# S6E1A1 register map
File version: 1.1
Registers are 8-bit, read-write, reset 0x0 unless marked. A register's access mark holds for its fields unless they carry their own. Offsets are from the block's base; [hi:lo] are bit positions; 'fields as' and 'values as' point back to an identical list.

## MFT0 — Multifunction Timer 0
Base 0x40020000
0x102 OCU_OCCP0 16-bit — OCU ch.0 Compare Value Store Register
0x106 OCU_OCCP1 16-bit — OCU ch.1 Compare Value Store Register
0x10A OCU_OCCP2 16-bit — OCU ch.2 Compare Value Store Register
0x10E OCU_OCCP3 16-bit — OCU ch.3 Compare Value Store Register
0x112 OCU_OCCP4 16-bit — OCU ch.4 Compare Value Store Register
0x116 OCU_OCCP5 16-bit — OCU ch.5 Compare Value Store Register
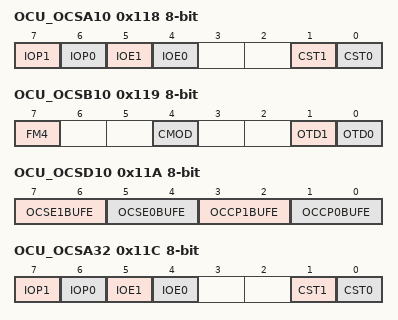
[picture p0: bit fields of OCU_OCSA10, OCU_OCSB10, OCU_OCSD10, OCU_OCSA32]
0x118 OCU_OCSA10 — OCU ch.1@0 Control Register A
  [7] IOP1 — Indicates that a match has already been detected between FRT's count value and OCCP(1) value at OCU ch.(1).
  [6] IOP0 — Indicates that a match has already been detected between FRT's count value and OCCP(0) value at OCU ch.(0).
  [5] IOE1 — Generates interrupt@ when ""1"" is set to OCSA.IOP1
  [4] IOE0 — Generates interrupt@ when ""1"" is set to OCSA.IOP0
  [1] CST1 — Enables the operation of OCU ch.(1)
  [0] CST0 — Enables the operation of OCU ch.(0)
0x119 OCU_OCSB10 — OCU ch.1@0 Control Register B
  [7] FM4 — Selects the OCU's operating mode
  [4] CMOD — Selects OCU's operation mode in combination with OCSC.MOD0 to MOD5
  [1] OTD1 — Indicates that the RT(1) output pin is in the High-level output state.
  [0] OTD0 — Indicates that the RT(0) output pin is in the High-level output state.
0x11A OCU_OCSD10 — OCU ch.1@0 Control Register D
  [7:6] OCSE1BUFE — Enable or disable the buffer register function of OCSE(1)
  [5:4] OCSE0BUFE — Enable or disable the buffer register function of OCSE(0)
  [3:2] OCCP1BUFE — Enable or disable the buffer register function of OCCP(1)
  [1:0] OCCP0BUFE — Enable or disable the buffer register function of OCCP(0)
0x11C OCU_OCSA32 — OCU ch.3@2 Control Register A
  fields as OCU_OCSA10
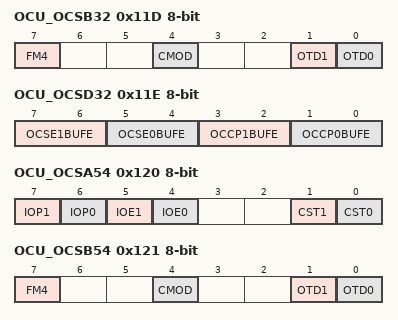
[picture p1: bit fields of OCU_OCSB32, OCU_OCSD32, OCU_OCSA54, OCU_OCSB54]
0x11D OCU_OCSB32 — OCU ch.3@2 Control Register B
  fields as OCU_OCSB10
0x11E OCU_OCSD32 — OCU ch.1@0 Control Register D
  fields as OCU_OCSD10
0x120 OCU_OCSA54 — OCU ch.5@4 Control Register A
  fields as OCU_OCSA10
0x121 OCU_OCSB54 — OCU ch.5@4 Control Register B
  fields as OCU_OCSB10
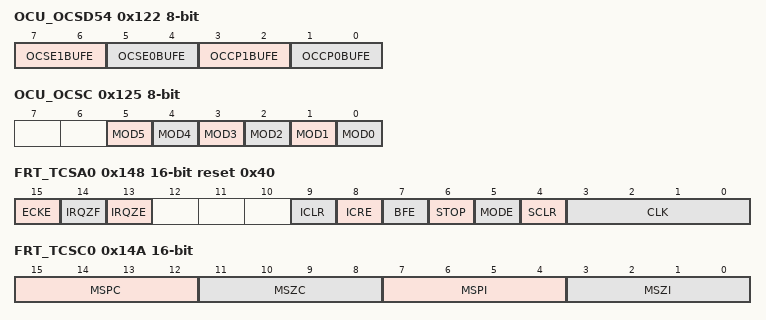
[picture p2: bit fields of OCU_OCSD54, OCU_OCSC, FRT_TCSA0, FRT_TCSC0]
0x122 OCU_OCSD54 — OCU ch.5@4 Control Register D
  fields as OCU_OCSD10
0x125 OCU_OCSC — OCU Control Register C
  [5] MOD5 — OCSC.MOD4 and OCSC.MOD5 determine the operation mode of OCU ch.4,h.5 in combination with OCSB54.CMOD
  [4] MOD4 — OCSC.MOD4 and OCSC.MOD5 determine the operation mode of OCU ch.4,h.5 in combination with OCSB54.CMOD
  [3] MOD3 — OCSC.MOD2 and OCSC.MOD3 determine the operation mode of OCU ch.2,h.3 in combination with OCSB32.CMOD
  [2] MOD2 — OCSC.MOD2 and OCSC.MOD3 determine the operation mode of OCU ch.2,h.3 in combination with OCSB32.CMOD
  [1] MOD1 — OCSC.MOD0 and OCSC.MOD1 determine the operation mode of OCU ch.0,h.1 in combination with OCSB10.CMOD
  [0] MOD0 — OCSC.MOD0 and OCSC.MOD1 determine the operation mode of OCU ch.0,h.1 in combination with OCSB10.CMOD
0x128 OCU_OCSE0 16-bit — OCU ch.0 Control Register E
  [15:0] OCSE — Specify the setting conditions of the OCU's matching detection register and the change conditions for output signals
0x12C OCU_OCSE1 32-bit — OCU ch.1 Control Register E
  [31:0] OCSE — Specify the setting conditions of the OCU's matching detection register and the change conditions for output signals
0x130 OCU_OCSE2 16-bit — OCU ch.2 Control Register E
  fields as OCU_OCSE0
0x134 OCU_OCSE3 32-bit — OCU ch.3 Control Register E
  fields as OCU_OCSE1
0x138 OCU_OCSE4 16-bit — OCU ch.4 Control Register E
  fields as OCU_OCSE0
0x13C OCU_OCSE5 32-bit — OCU ch.5 Control Register E
  fields as OCU_OCSE1
0x142 FRT_TCCP0 16-bit reset 0xFFFF — FRT-ch.0 Cycle Setting Register
0x146 FRT_TCDT0 16-bit — FRT-ch.0 Count Value Register
0x148 FRT_TCSA0 16-bit reset 0x40 — FRT-ch.0 Control Register A
  [15] ECKE — Uses an external input clock (FRCK) as FRT's count clock
  [14] IRQZF — Zero interrupt flag
  [13] IRQZE — Generates interrupt@ when ""1"" is set to TCSA.IRQZF
  [9] ICLR — Interrupt flag
  [8] ICRE — Generates interrupt when ""1"" is set to TCSA.ICLR
  [7] BFE — Enables TCCP's buffer function
  [6] STOP — Puts FRT in stopping state
  [5] MODE — FRT's count mode
  [4] SCLR wo — FRT operation state initialization request
  [3:0] CLK — FRT clock cycle
0x14A FRT_TCSC0 16-bit — FRT-ch.0 Control Register C
  [15:12] MSPC ro — Sets the number of masked Zero value detections
  [11:8] MSZC ro — Sets the number of masked Peak value detections
  [7:4] MSPI — Reads the current counter value from a Zero value detection mask counter
  [3:0] MSZI — Reads the current counter value from a Peak value detection mask counter
0x14E FRT_TCCP1 16-bit reset 0xFFFF — FRT-ch.1 Cycle Setting Register
0x152 FRT_TCDT1 16-bit — FRT-ch.1 Count Value Register
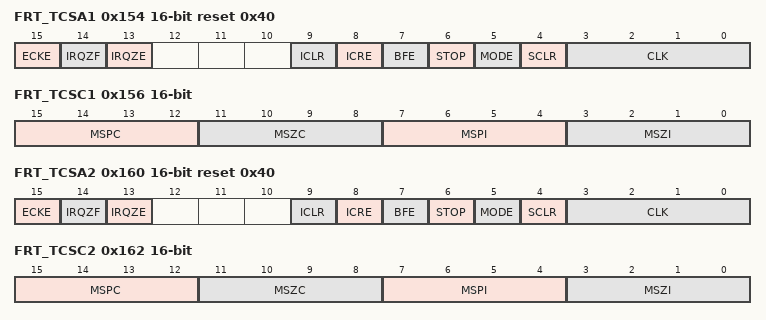
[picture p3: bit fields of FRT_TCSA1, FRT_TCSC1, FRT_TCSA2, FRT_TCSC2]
0x154 FRT_TCSA1 16-bit reset 0x40 — FRT-ch.1 Control Register A
  fields as FRT_TCSA0
0x156 FRT_TCSC1 16-bit — FRT-ch.1 Control Register C
  fields as FRT_TCSC0
0x15A FRT_TCCP2 16-bit reset 0xFFFF — FRT-ch.2 Cycle Setting Register
0x15E FRT_TCDT2 16-bit — FRT-ch.2 Count Value Register
0x160 FRT_TCSA2 16-bit reset 0x40 — FRT-ch.2 Control Register A
  fields as FRT_TCSA0
0x162 FRT_TCSC2 16-bit — FRT-ch.2 Control Register C
  fields as FRT_TCSC0
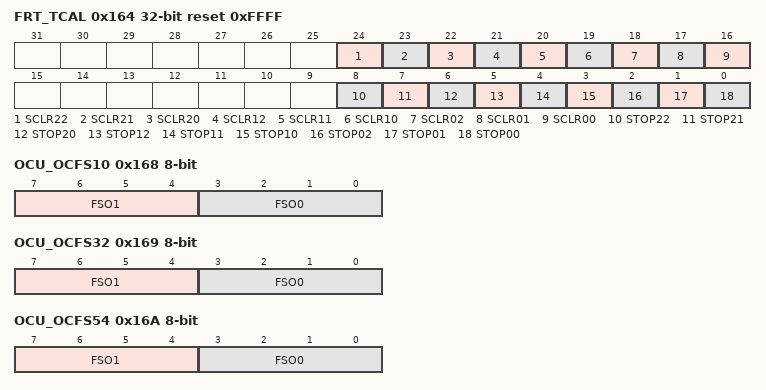
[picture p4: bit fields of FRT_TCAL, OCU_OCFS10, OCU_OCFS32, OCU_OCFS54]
0x164 FRT_TCAL 32-bit reset 0xFFFF — FRT Simultaneous Start Control Register
  [24] SCLR22 wo — Processes simultaneous writes to relevant TCSA.SCLR register 22
  [23] SCLR21 wo — Processes simultaneous writes to relevant TCSA.SCLR register 21
  [22] SCLR20 wo — Processes simultaneous writes to relevant TCSA.SCLR register 20
  [21] SCLR12 wo — Processes simultaneous writes to relevant TCSA.SCLR register 12
  [20] SCLR11 wo — Processes simultaneous writes to relevant TCSA.SCLR register 11
  [19] SCLR10 wo — Processes simultaneous writes to relevant TCSA.SCLR register 10
  [18] SCLR02 wo — Processes simultaneous writes to relevant TCSA.SCLR register 02
  [17] SCLR01 wo — Processes simultaneous writes to relevant TCSA.SCLR register 01
  [16] SCLR00 wo — Processes simultaneous writes to relevant TCSA.SCLR register 00
  [8] STOP22 — Processes simultaneous writes/reads to relevant TCSA.STOP bit 22
  [7] STOP21 — Processes simultaneous writes/reads to relevant TCSA.STOP bit 21
  [6] STOP20 — Processes simultaneous writes/reads to relevant TCSA.STOP bit 20
  [5] STOP12 — Processes simultaneous writes/reads to relevant TCSA.STOP bit 12
  [4] STOP11 — Processes simultaneous writes/reads to relevant TCSA.STOP bit 11
  [3] STOP10 — Processes simultaneous writes/reads to relevant TCSA.STOP bit 10
  [2] STOP02 — Processes simultaneous writes/reads to relevant TCSA.STOP bit 02
  [1] STOP01 — Processes simultaneous writes/reads to relevant TCSA.STOP bit 01
  [0] STOP00 — Processes simultaneous writes/reads to relevant TCSA.STOP bit 00
0x168 OCU_OCFS10 — OCU ch.1@0 Connecting FRT Select Register
  [7:4] FSO1 — Connects FRT ch.x to OCU ch.1
  [3:0] FSO0 — Connects FRT ch.x to OCU ch.0
0x169 OCU_OCFS32 — OCU ch.3@2 Connecting FRT Select Register
  fields as OCU_OCFS10
0x16A OCU_OCFS54 — OCU ch.5@4 Connecting FRT Select Register
  fields as OCU_OCFS10
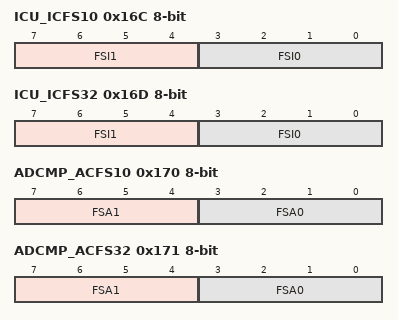
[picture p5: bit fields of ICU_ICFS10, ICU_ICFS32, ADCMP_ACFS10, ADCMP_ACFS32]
0x16C ICU_ICFS10 — ICU ch.1@0 Connecting FRT Select Register
  [7:4] FSI1 — Connects FRT ch.x to ICU ch.(1)
  [3:0] FSI0 — Connects FRT ch.x to ICU ch.(0)
0x16D ICU_ICFS32 — ICU ch.3@2 Connecting FRT Select Register
  fields as ICU_ICFS10
0x170 ADCMP_ACFS10 — ADCMP Ch1@0 Connecting FRT Select Register
  [7:4] FSA1 — Specify the FRT ch.x to be connected to ADCMP ch.(1)
  [3:0] FSA0 — Specify the FRT ch.x to be connected to ADCMP ch.(0)
0x171 ADCMP_ACFS32 — ADCMP Ch3@2 Connecting FRT Select Register
  fields as ADCMP_ACFS10
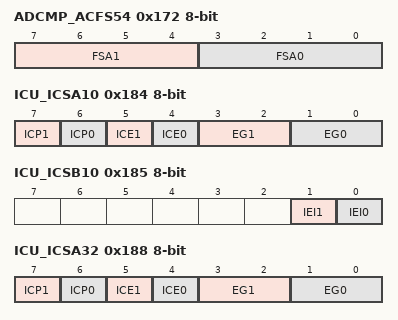
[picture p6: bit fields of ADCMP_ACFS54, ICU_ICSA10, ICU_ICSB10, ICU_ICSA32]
0x172 ADCMP_ACFS54 — ADCMP Ch5@4 Connecting FRT Select Register
  fields as ADCMP_ACFS10
0x176 ICU_ICCP0 16-bit ro — ICU ch.0 Capture value store register
0x17A ICU_ICCP1 16-bit ro — ICU ch.1 Capture value store register
0x17E ICU_ICCP2 16-bit ro — ICU ch.2 Capture value store register
0x182 ICU_ICCP3 16-bit ro — ICU ch.3 Capture value store register
0x184 ICU_ICSA10 — ICU ch.1@0 Control Register A
  [7] ICP1 — Indicates that a valid edge has been detected at ICU ch.(1) and the capture operation has been performed
  [6] ICP0 — Indicates that a valid edge has been detected at ICU ch.(0) and the capture operation has been performed
  [5] ICE1 — Generates interrupt@ when ""1"" is set to ICSA.ICP1.
  [4] ICE0 — Generates interrupt@ when ""1"" is set to ICSA.ICP0.
  [3:2] EG1 — Enables/disables the operation of ICU-ch.(1) and selects a valid edge(s)
  [1:0] EG0 — Enables/disables the operation of ICU-ch.(0) and selects a valid edge(s)
0x185 ICU_ICSB10 ro — ICU ch.1@0 Control Register B
  [1] IEI1 — Indicates the latest valid edge of ICU-ch.(1)
  [0] IEI0 — Indicates the latest valid edge of ICU-ch.(0)
0x188 ICU_ICSA32 — ICU ch.3@2 Control Register A
  fields as ICU_ICSA10
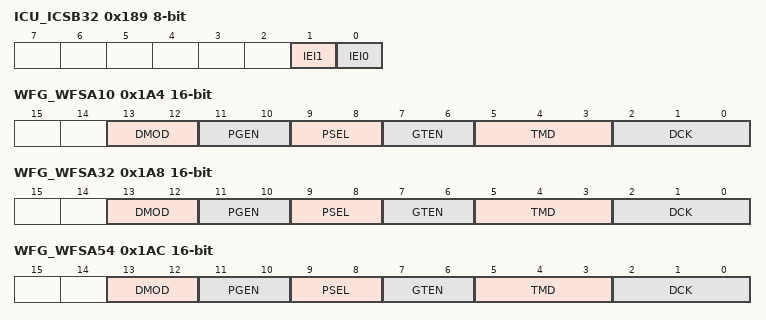
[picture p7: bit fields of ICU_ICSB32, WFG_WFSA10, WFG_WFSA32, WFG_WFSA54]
0x189 ICU_ICSB32 ro — ICU ch.3@2 Control Register B
  fields as ICU_ICSB10
0x18E WFG_WFTF10 16-bit — WFG ch1@0 Pulse Counter Value Register
0x190 WFG_WFTA10 16-bit — WFG ch.1@0 Timer Value Register A
0x192 WFG_WFTB10 16-bit — WFG ch.1@0 Timer Value Register B
0x196 WFG_WFTF32 16-bit — WFG ch3@2 Pulse Counter Value Register
0x198 WFG_WFTA32 16-bit — WFG ch.3@2 Timer Value Register A
0x19A WFG_WFTB32 16-bit — WFG ch.3@2 Timer Value Register B
0x19E WFG_WFTF54 16-bit — WFG ch.5@4 Timer Value Register A
0x1A0 WFG_WFTA54 16-bit — WFG ch.5@4 Timer Value Register A
0x1A2 WFG_WFTB54 16-bit — WFG ch.5@4 Timer Value Register B
0x1A4 WFG_WFSA10 16-bit — WFG ch.10 Control Register A
  [13:12] DMOD — Specifies which polarity will be used to output the non-overlap signal
  [11:10] PGEN — Specifies how to reflect the CH_PPG signal that is input to each channel of WFG on WFG output
  [9:8] PSEL — The PPG timer unit to be used at each channel of WFG
  [7:6] GTEN — The CH_GATE signal for each channel of WFG
  [5:3] TMD — WFG's operation mode
  [2:0] DCK — Clock cycle of the WFG timer
0x1A8 WFG_WFSA32 16-bit — WFG ch.32 Control Register A
  fields as WFG_WFSA10
0x1AC WFG_WFSA54 16-bit — WFG ch.54 Control Register A
  fields as WFG_WFSA10
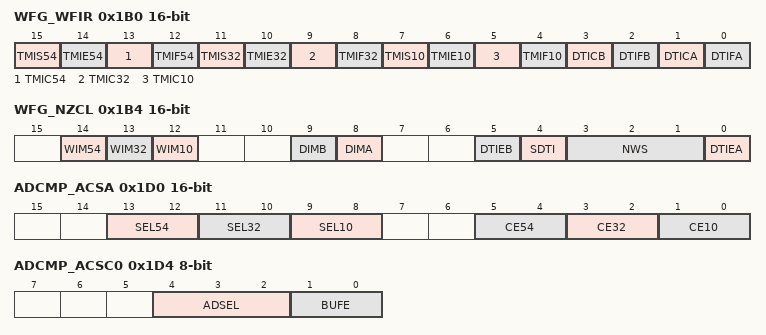
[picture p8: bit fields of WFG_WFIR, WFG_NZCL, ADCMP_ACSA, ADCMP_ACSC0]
0x1B0 WFG_WFIR 16-bit — WFG Interrupt Control Register
  [15] TMIS54 wo — Stops the WFG54 timer
  [14] TMIE54 — Starts the WFG54 timer
  [13] TMIC54 wo — Clears WFIR.TMIF54 and deasserts the WFG54 timer interrupt signal.
  [12] TMIF54 ro — Indicates that WFG54 timer interrupt has been generated.
  [11] TMIS32 wo — Stops the WFG32 timer
  [10] TMIE32 — Starts the WFG32 timer
  [9] TMIC32 wo — Clears WFIR.TMIF32 and deasserts the WFG32 timer interrupt signal.
  [8] TMIF32 ro — Indicates that WFG32 timer interrupt has been generated.
  [7] TMIS10 wo — Stops the WFG10 timer
  [6] TMIE10 — Starts the WFG10 timer
  [5] TMIC10 wo — Clears WFIR.TMIF10 and deasserts the WFG10 timer interrupt signal.
  [4] TMIF10 ro — Indicates that WFG10 timer interrupt has been generated.
  [3] DTICB wo — Clears DTIFB bit
  [2] DTIFB ro — Detects DTTIX signal input via analog noise filter
  [1] DTICA wo — Clears the DTIFA interrupt flag
  [0] DTIFA ro — Detects the event of DTTIX signal input via digital noise-canceller
0x1B4 WFG_NZCL 16-bit — NZCL Control Register
  [14] WIM54 — Selects whether a WFG54 reload timer interrupt is masked when the WFIR.TMIF54 flag is set
  [13] WIM32 — Selects whether a WFG32 reload timer interrupt is masked when the WFIR.TMIF32 flag is set
  [12] WIM10 — Selects whether a WFG10 reload timer interrupt is masked when the WFIR.TMIF10 flag is set
  [9] DIMB — Selects whether a DTIF interrupt is masked when the WFIR.TIFDTIFB flag is set
  [8] DIMA — Selects whether a DTIF interrupt is masked when the WFIR.DTIFA flag is set
  [5] DTIEB — Selects whether to set the WFIR.DTIFB flag for the path from the DTTIX pin for input signal to an analog noise filter
  [4] SDTI wo — Forcibly generates DTIF interrupt
  [3:1] NWS — Noise-canceling width of the noise-canceller for the DTTIX pin
  [0] DTIEA — Selects whether the WFIR.DTIFA register is set for the path via digital noise filter from the DTTIX input pin
0x1BA ADCMP_ACMP0 16-bit — ADCMP Ch.0 Compare Value Store Register
  [15:0] ACMP — Specify an AD conversion start time
0x1BE ADCMP_ACMP1 16-bit — ADCMP Ch.1 Compare Value Store Register
  [15:0] ACMP — Specify an AD conversion start time
0x1C2 ADCMP_ACMP2 16-bit — ADCMP Ch.2 Compare Value Store Register
  [15:0] ACMP — Specify an AD conversion start time
0x1C6 ADCMP_ACMP3 16-bit — ADCMP Ch.3 Compare Value Store Register
  [15:0] ACMP — Specify an AD conversion start time
0x1CA ADCMP_ACMP4 16-bit — ADCMP Ch.4 Compare Value Store Register
  [15:0] ACMP — Specify an AD conversion start time
0x1CE ADCMP_ACMP5 16-bit — ADCMP Ch.5 Compare Value Store Register
  [15:0] ACMP — Specify an AD conversion start time
0x1D0 ADCMP_ACSA 16-bit — ADCMP Control Register A
  [13:12] SEL54 — Selects compatible operation of ADCMP ch.5 and ch.4 with FM3 Family products
  [11:10] SEL32 — Selects compatible operation of ADCMP ch.3 and ch.2 with FM3 Family products
  [9:8] SEL10 — Selects compatible operation of ADCMP ch.1 and ch.0 with FM3 Family products
  [5:4] CE54 — Enables/disables compatibility of ADCMP ch.5 and ch.4 with FM3 Family products
  [3:2] CE32 — Enables/disables compatibility of ADCMP ch.3 and ch.2 with FM3 Family products
  [1:0] CE10 — Enables/disables compatibility of ADCMP ch.1 and ch.0 with FM3 Family products
0x1D4 ADCMP_ACSC0 — ADCMP Ch.0 Control Register C
  [4:2] ADSEL — Specify the destinations of ADC start signals that are output by ADCMP
  [1:0] BUFE — Select enable/disable and transfer timing for buffer function of the ACMP register
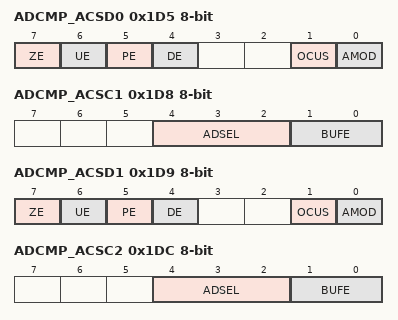
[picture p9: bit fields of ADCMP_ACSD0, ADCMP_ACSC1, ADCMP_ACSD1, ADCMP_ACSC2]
0x1D5 ADCMP_ACSD0 — ADCMP Ch.0 Control Register D
  [7] ZE — Enables/disables the operation of the ADCMP when the FRT is ""0x0000""
  [6] UE — Nables/disables the operation of the ADCMP that is counting up for the connected FRT
  [5] PE — Enables/disables the operation of the ADCMP that is counting down at the Peak value of the connected FRT
  [4] DE — Enables/disables the operation of the ADCMP that is counting down for the connected FRT
  [1] OCUS — Selects the OCU OCCP register that will become the start for offset start
  [0] AMOD — Selects operation mode for ADCMP
0x1D8 ADCMP_ACSC1 — ADCMP Ch.1 Control Register C
  fields as ADCMP_ACSC0
0x1D9 ADCMP_ACSD1 — ADCMP Ch.1 Control Register D
  fields as ADCMP_ACSD0
0x1DC ADCMP_ACSC2 — ADCMP Ch.2 Control Register C
  fields as ADCMP_ACSC0
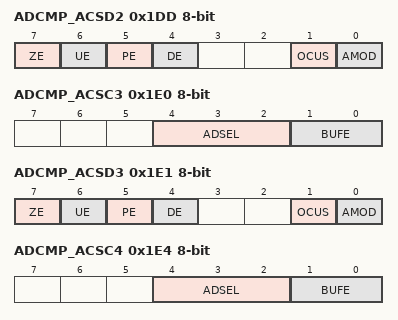
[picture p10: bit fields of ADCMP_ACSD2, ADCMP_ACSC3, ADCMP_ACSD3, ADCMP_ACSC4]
0x1DD ADCMP_ACSD2 — ADCMP Ch.2 Control Register D
  fields as ADCMP_ACSD0
0x1E0 ADCMP_ACSC3 — ADCMP Ch.3 Control Register C
  fields as ADCMP_ACSC0
0x1E1 ADCMP_ACSD3 — ADCMP Ch.3 Control Register D
  fields as ADCMP_ACSD0
0x1E4 ADCMP_ACSC4 — ADCMP Ch.4 Control Register C
  fields as ADCMP_ACSC0
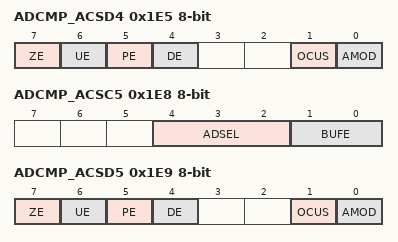
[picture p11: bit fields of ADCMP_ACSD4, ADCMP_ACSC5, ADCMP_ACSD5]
0x1E5 ADCMP_ACSD4 — ADCMP Ch.4 Control Register D
  fields as ADCMP_ACSD0
0x1E8 ADCMP_ACSC5 — ADCMP Ch.5 Control Register C
  fields as ADCMP_ACSC0
0x1E9 ADCMP_ACSD5 — ADCMP Ch.5 Control Register D
  fields as ADCMP_ACSD0
